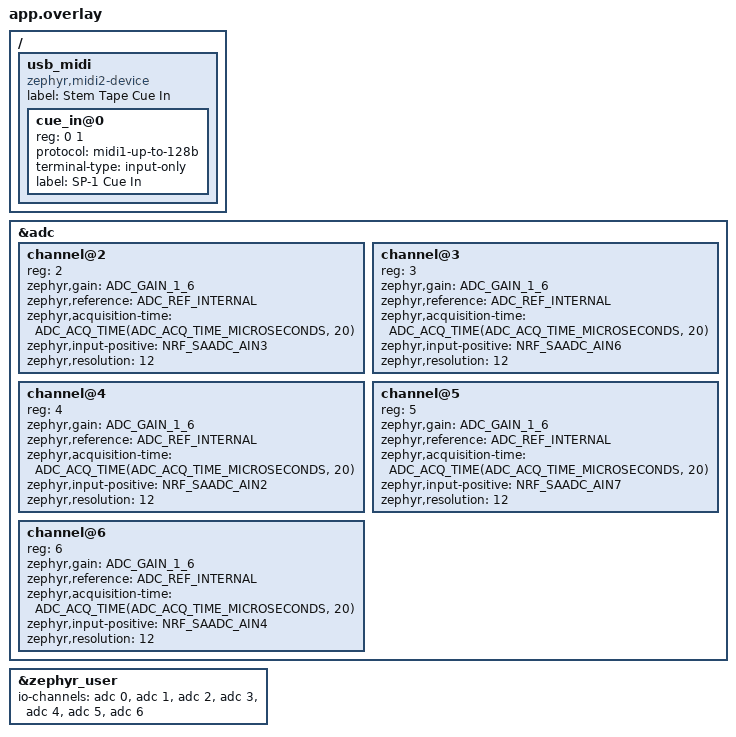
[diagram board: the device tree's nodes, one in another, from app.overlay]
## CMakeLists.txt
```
cmake_minimum_required(VERSION 3.20.0)
find_package(Zephyr REQUIRED HINTS $ENV{ZEPHYR_BASE})
project(stemtape-player)

include(${ZEPHYR_BASE}/samples/subsys/usb/common/common.cmake)

# src/main.c and src/sp1_emmc.c are real derivatives of the proven Tape
# Looper (firmware/src/main.c, firmware/src/sp1_emmc.c) -- see main.c's
# provenance banner.
#
# GATE 1: src/st_midi_queue.c is the pure, host-testable USB-MIDI receive
# decode + bounded event queue (see st_midi_queue.h). main.c's real
# rx_packet_cb is a thin adapter that calls st_midi_decode_ump32() on the
# incoming UMP word -- the SAME function tests/test_stemtape_player.c
# exercises on the host -- so this is genuinely linked, not a parallel
# unwired module.
#
# STEM TAPE v1.1 (docs/stem-tape-transfer-v1.1.md is the current,
# authoritative contract): src/st_crc32.c, src/st_checksum32.c,
# src/st_sector_v11.c, src/st_stix.c, src/st_stcp.c, src/st_ab_session.c --
# the real STIX v2 index parse/validate/select, STSC sector codec, A/B
# region layout + STCP capability reply, and the stateful write-safety
# session gate (see each header's own doc) -- are linked: main.c's real
# 'Q' handler and boot-time A/B selection call these SAME pure functions
# tests/test_stem_v11.c exercises against the frozen Lovable handoff
# fixtures. st_crc32.c is linked for st_stix.c's own record-integrity CRC
# (st_stix_block_crc()), not for any v1.0 purpose.
#
# Phase 2 slice 2: src/st_stem_mix.c -- the pure, real-time-safe 4-stem-
# to-stereo mixdown (see st_stem_mix.h's own doc) -- is now linked and
# genuinely called: main.c's looper_audio_block() (PASS C) calls
# st_stem_mix_frame() on frames st11_sector_decode_frame() decodes from a
# real stored song's own sector data, feeding the SP-1's existing physical
# I2S output. Was added unlinked, host-test-only, in an earlier commit
# (see git log); the slice-2 commit gave it its real caller, per this
# file's own established policy below.
#
# Phase 2 slice 3B: src/st_stem_stream.c -- the pure stored-song
# CONTINUOUS streaming state machine (see st_stem_stream.h's own doc) --
# is now linked and genuinely called: streamer_thread() seeds it from the
# selected song's own real STIX geometry and validates every sector (not
# just the first) through it; audio_thread (looper_audio_block()'s own
# PASS C) is its EXCLUSIVE owner as of slice 3B.1's concurrency
# correction, driving its per-frame song-position/sector-readiness/
# underrun bookkeeping. Was added unlinked, host-test-only, in slice 3A
# (see git log); slice 3B gave it its real caller, per this file's own
# established policy.
#
# Phase 2 slice 3B.1 (concurrency correction): src/st_stem_bufmbox.c --
# the formally specified, lock-free single-producer/single-consumer
# double-buffer publication mailbox (see st_stem_bufmbox.h's own full
# protocol spec) -- replaces slice 3B's `volatile`-fields-plus-
# documented-write-order cross-thread handoff between streamer_thread
# (producer) and audio_thread (consumer) with real atomics and acquire/
# release ordering. Compiled with -DST_STEM_BUFMBOX_ZEPHYR (below) so its
# atomic primitives resolve to Zephyr's own atomic_t, unconditionally
# sequentially consistent on every architecture Zephyr supports --
# strictly stronger than the acquire/release the protocol requires. The
# SAME source file, built instead against C11 <stdatomic.h> with the
# minimal acquire/release ordering the protocol actually needs, is what
# tests/test_stem_bufmbox.c's real concurrent-pthread host tests exercise
# (see that file's own doc comment for why that is a faithful stand-in,
# and where the faithfulness gap actually is).
#
# Phase 3 control-matrix (momentary hold-to-solo, corrected): src/
# st_track_hold.c -- the pure, host-tested momentary hold-timing state
# machine (see st_track_hold.h's own doc comment for the semantics, and
# why this replaced a first version that wrongly toggled solo once at
# release -- a latch, not the momentary behavior actually specified) --
# is linked and genuinely called: main.c's own track-button scan loop
# ticks one instance per track every scan pass, and looper_audio_block()/
# led_service() both read the resulting trk[].solo state it drives.
#
# Phase 3 control-matrix (beat-sync LED slice): src/st_beat_phase.c -- the
# pure, host-tested, RAM-only beat-phase computation (see that file's own
# doc comment: the selected STIX record's own bpm_q8/downbeat_frame are
# the sole authoritative tempo source, sector-header timing is cross-
# checked for consistency only, and phase is always re-derived from the
# master song_frame position's own atomic mirror -- never a second,
# independently-ticking clock) -- is linked and genuinely called: main.c's
# own streamer_thread() boot code publishes the timing snapshot once (from
# the SAME already-read STIX record slice 3B/3B.1 already consume for
# geometry), audio_block_epilogue() publishes the song-position mirror once
# per block, and led_service() calls st_beat_pulse() on both of those every
# control pass. EVERY function in this file has a real caller: the module
# once also exported st_beat_phase_on_beat()/st_beat_led_decide(), which
# lost their caller when the eight LEDs got a single semantic owner, and
# have since been DELETED rather than left compiled in and unreachable.
#
# The OLD, now-retired v1.0 Gate 2 contract's own engine -- src/
# st_storage_layout.c, src/st_sector_codec.c, src/st_transfer.c, src/
# st_library_io.c, src/st_xfer_wire.c, and src/st_stem_validate.c (an
# even earlier, already-superseded design within that same v1.0 line) --
# is DELIBERATELY NOT linked here: main.c no longer calls any command
# handler or adapter that reaches these files' functions at all (the
# v1.1 migration deleted that dispatch code, not merely disabled it), so
# there is no path from this target's command dispatch to their own
# emmc_write_blocks() call sites, and no v1.0 write path is ever present
# in this ELF -- v1.0 and v1.1 can never both hold a live write path in
# the same build, by construction. These files stay in the tree and keep
# their own host tests (tests/test_stemtape_player.c) for regression
# evidence only; a follow-up commit extends the strict persistence safety
# gate to check their symbols are absent from the built ELF directly, as
# positive proof rather than relying on this list alone.
#
# NOT included here (compiled only into tests/test_stemtape_player.c's host
# test binary, not into this firmware target): led_duty.c/led_render.c/
# led_render_policy.c, st_gesture.c, st_scrub.c, st_led_pattern.c --
# st_gesture.c/st_scrub.c/st_led_pattern.c implemented an earlier,
# superseded standalone protocol/runtime design (see git log); main.c
# still drives LEDs directly (its own GPIO+soft-PWM driver, inherited
# from the Tape Looper). Preserved and still host-tested for reference;
# deliberately NOT linked into this ELF so as not to present unwired
# modules as part of the real runtime.
#
# Upload-reliability phase, Slice C2: src/st_bulk_xfer.c -- the pure wire-
# contract parser/builder + per-session sequence state machine behind the
# new 'U' bulk verified-sector command (see st_bulk_xfer.h's own doc and
# docs/stem-tape-bulk-upload-v1.md) -- is now linked and genuinely called:
# main.c's real xfer_bulk_write_sector() (xfer_service()'s 'U' handler)
# calls st_bulk_parse_header()/st_bulk_build_response()/st_bulk_seq_check()/
# st_bulk_seq_advance() against the real CDC/eMMC environment. Was added
# unlinked, host-test-only, in Slice C1 (see git log); this slice gave it
# its real caller, per this file's own established policy (see
# st_stem_stream.c's own identical slice-3A/3B split above).
# Tape transport inertia: src/st_inertia.c -- the pure spin-up/spin-down
# envelope. It is a 0..1 multiplier on the transport rate and knows nothing
# about audio; main.c's stem run loop applies it to the shared playhead and
# src/st_resample.h (header-only, no translation unit) converts between the
# source-frame and output-frame domains that a rate other than 1x separates.
# Host-tested in tests/test_inertia.c.

# Rocker semitone control: src/st_pitch.c -- the song's pitch, on the same
# equal-tempered 2^(k/12) grid the inherited Tape Looper's own semitone
# double-click uses (firmware/src/main.c's k_semi_q16), subdivided to half
# steps. It is a tape varispeed: the value is a playback RATE, so pitch and
# time move together exactly as they do in the Looper, and no time-stretching
# was added. Host-tested in tests/test_pitch.c, which re-derives the Looper's
# whole-semitone table out of this one and compares it entry by entry.

# LED MVP (single semantic owner): src/st_led_mvp.c -- the pure,
# host-tested decision that turns real runtime state into one complete
# eight-LED frame, plus the local battery classifier (see st_led_mvp.h) --
# is linked and genuinely called: main.c's led_service() fills
# st_led_inputs_t from the live transport/mixer/charger state, calls
# st_led_mvp_decide(), and renders the result through the existing
# TIMER3/GPIO soft-PWM masks. It is the ONLY thing that writes those masks
# in normal running.
#
# RE-LINKED: src/st_stem_meter.c -- the per-stem envelope follower and
# brightness curve, one instance per stem.
#
# It was unlinked once, on the reasoning that "a level meter is not the
# stable readable indication the LED contract specifies -- a quiet passage
# dimmed a stem that was audible". That reasoning is reversed on the
# product's own terms: a quiet passage SHOULD dim its stem, because the Track
# row's job is to show what each part of the arrangement is doing, and a row
# that reads the same whether a stem is playing or resting shows nothing at
# all. The stable indication the contract wanted is the SIDE row, which still
# has it -- S4 carries the beat, unchanged.
#
# The module owns no clock and takes no tempo input; it converts a stream of
# per-stem peaks into a brightness. Host-tested in tests/test_stem_meter.c
# (the arithmetic) and tests/test_led_audio_reactive.c (the five acceptance
# behaviours, against synthesised drum/pad/vocal material).
target_sources(app PRIVATE
	src/main.c
	src/sp1_emmc.c
	src/st_midi_queue.c
	src/st_crc32.c
	src/st_checksum32.c
	src/st_sector_v11.c
	# v1.2 song-planar addressing. main.c's read path calls st_pl_group_block(),
	# st_pl_validate() and st_pl_decode_frame() on every fetch and every frame,
	# so this is not optional -- omitting it links to nothing and the build dies
	# at the first link pass with no zephyr.elf, which is exactly what happened.
	src/st_planar.c
	src/st_stix.c
	src/st_stcp.c
	src/st_ab_session.c
	src/st_bulk_xfer.c
	src/st_stem_mix.c
	src/st_stem_stream.c
	src/st_stem_bufmbox.c
	src/st_track_hold.c
	src/st_ladder.c
	src/st_ctl.c
	src/st_pwr_hold.c
	src/st_pwr_idle.c
	src/st_loop.c
	src/st_fx.c
	src/st_fx_ctl.c
	src/st_inertia.c
	src/st_pitch.c
	src/st_fnplay.c
	src/st_readcost.c
	src/st_beat_phase.c
	src/st_stem_meter.c
	src/st_led_mvp.c
)

# See firmware/CMakeLists.txt's identical note: the batchbuf/meta-block code
# (inherited unchanged in this derivative) type-puns static uint8_t[]
# storage through other lvalue types; -fno-strict-aliasing removes the TBAA
# assumption that would make that idiom undefined.
target_compile_options(app PRIVATE -fno-strict-aliasing)

# Selects st_stem_bufmbox.h's real-Zephyr-atomic_t backend for this
# firmware target only -- the host test build (plain `cc`, no Zephyr
# headers available) never defines this, so it takes the C11
# <stdatomic.h> backend instead. See st_stem_bufmbox.h's own doc comment.
target_compile_definitions(app PRIVATE ST_STEM_BUFMBOX_ZEPHYR)

target_link_libraries(app PRIVATE m)

# ---- AIN1 CALIBRATION CAPTURE ------------------------------------------
# OFF unless -DST_VOL_CAL=1 is passed on the west/cmake command line. An
# explicit hook rather than EXTRA_COMPILE_DEFINITIONS, which is not a
# dependable Zephyr variable across versions.
#
# The capture prints the raw AIN1 rail so the Volume-/Volume+ chord value can
# be measured; the FX overlay cannot decode that chord until it is. It must
# never reach a shipped image, which two independent checks enforce: the
# safety gate greps main.c's own #define, and the CI build compares `strings`
# on the two BINs.
if(ST_VOL_CAL)
  zephyr_compile_definitions(ST_VOL_CAL=1)
  message(STATUS "AIN1 CALIBRATION CAPTURE ENABLED -- not a shippable image")
endif()
```

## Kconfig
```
# Stem Tape Player application Kconfig.
#
# Pulls in the common USB sample options (CONFIG_SAMPLE_USBD_VID/PID/PRODUCT/...)
# consumed by the vendored sample_usbd_init.c device_next bring-up helper, then
# the standard Zephyr Kconfig tree. Mirrors firmware/Kconfig and
# firmware/stemtape/Kconfig exactly -- this file was simply never needed
# before src/main.c became a real derivative of the Tape Looper and started
# using CONFIG_SAMPLE_USBD_* (prj.conf) for its own USB device identity.

source "samples/subsys/usb/common/Kconfig.sample_usbd"

source "Kconfig.zephyr"
```

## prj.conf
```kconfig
# ---- Stem Tape Player: derived from the real Tape Looper's prj.conf ----
#
# src/main.c is now a real derivative of the proven firmware/src/main.c (see
# its provenance banner). USB device_next carries CDC console + class-
# compliant incoming USB-MIDI 2.0 (CONFIG_USBD_MIDI2_CLASS=y) only.
#
# STEM TAPE: UAC2 (USB audio class) playback -- CONFIG_USBD_AUDIO2_CLASS and
# its two feedback-workaround options below -- is REMOVED as of this change.
# Product decision: it was added earlier under the mistaken assumption that
# KO II cue control depended on it. Cue control actually uses incoming USB
# MIDI only, and song loading uses the companion's own transfer protocol
# over the CDC console (unaffected). Stored four-stem playback now
# exclusively owns the SP-1 audio output. See main.c's own top-of-file
# comment, and the CI "Effective configuration assertion" and "USB
# descriptor assertion" steps, which now prove CONFIG_USBD_AUDIO2_CLASS is
# unset and no UAC2 descriptor material is linked.
#
# Incoming MIDI drives KO II pad cue control via a standalone MIDI bridge;
# there is no outgoing MIDI and no MIDI clock in this slice. ADC (button
# ladders + faders), I2C (codec bring-up), I2S (audio out), watchdog, and
# the failsafes are all still needed, same as the classic looper. This file
# otherwise mirrors firmware/prj.conf (see that file for the per-option
# rationale comments); it does NOT invent any new Kconfig option beyond
# what firmware/prj.conf already proves builds and runs on this exact
# board, plus the MIDI2 option firmware/prj.conf itself documents.

CONFIG_PM=y
CONFIG_PM_DEVICE=n
CONFIG_LOG=n
CONFIG_ASSERT=n
CONFIG_USE_SEGGER_RTT=n
CONFIG_IDLE_STACK_SIZE=128
CONFIG_ISR_STACK_SIZE=512
CONFIG_WATCHDOG=y

# ---- FAILSAFES: catch stack overflow / bad memory access cleanly (MPU guard +
# stack canary). Any fatal fault is turned into a reboot by k_sys_fatal_error_handler
# in main.c, and the 4 s watchdog is the final backstop for a hang. ----
CONFIG_HW_STACK_PROTECTION=y
CONFIG_STACK_SENTINEL=y
CONFIG_REBOOT=y
CONFIG_CLOCK_CONTROL=y
CONFIG_CLOCK_CONTROL_NRF_K32SRC_SYNTH=y

# ---- USB-serial diagnostics console (CDC ACM) ----
CONFIG_PRINTK=y
CONFIG_SERIAL=y
CONFIG_CONSOLE=y
CONFIG_UART_CONSOLE=y
CONFIG_UART_LINE_CTRL=y
CONFIG_UART_INTERRUPT_DRIVEN=y

# ---- USB device_next: CDC console + incoming USB-MIDI only. ----
# SP1XFER!/xfer_service() still rides the CDC ACM console exactly as in
# the classic looper; every 'W'/'F'/'X' verb remains read-only-safe (see
# main.c). CONFIG_USBD_MIDI2_CLASS=y adds a class-compliant incoming-only
# USB-MIDI 2.0 endpoint (see app.overlay's usb_midi node and main.c's
# rx_packet_cb) -- no outgoing MIDI, no MIDI clock.
CONFIG_USB_DEVICE_STACK_NEXT=y
CONFIG_USBD_MIDI2_CLASS=y
CONFIG_USBD_CDC_ACM_CLASS=y
CONFIG_CDC_ACM_SERIAL_INITIALIZE_AT_BOOT=n
CONFIG_HWINFO=y
# Distinct PID from both the classic looper (0x5210) and stock SP-1 firmware,
# so a host never caches the wrong driver/identity across firmware swaps.
CONFIG_SAMPLE_USBD_VID=0x1915
CONFIG_SAMPLE_USBD_PID=0x5211
CONFIG_SAMPLE_USBD_MANUFACTURER="softmodded"
CONFIG_SAMPLE_USBD_PRODUCT="Stem Tape Audio"
CONFIG_THREAD_RUNTIME_STATS=y
CONFIG_SCHED_THREAD_USAGE=y
# STACK HIGH-WATER. Fills every thread stack with a known pattern at creation
# so k_thread_stack_space_get() can report how much has ever been touched.
# controls_diag() prints it on the STACK line. This exists because the RAM
# audit is not allowed to change a stack size from a guess: 12,672 bytes of
# stack are allocated across main/streamer/audio/midi/idle/ISR and none of
# those numbers has ever been measured against real use. Costs one memset per
# thread at boot and nothing at run time.
CONFIG_INIT_STACKS=y
CONFIG_SAMPLE_USBD_MAX_POWER=50

# ---- ADC for the button ladders / faders ----
CONFIG_ADC=y

# ---- I2C to the audio codecs (CS42L42 / TAS2505) ----
CONFIG_I2C=y

# ---- I2S audio out (nRF master) ----
CONFIG_I2S=y
CONFIG_I2S_NRFX=y
CONFIG_FPU=y
# See firmware/CMakeLists.txt's matching note: -O2 is unsafe for this
# codebase's mixer/eMMC timing (latent signed-overflow UB the classic looper
# already documents). Stay on the default -Os here too.

CONFIG_MAIN_STACK_SIZE=4096

# ---- Always-dim LEDs: the soft-PWM LED timer ISR (main.c's led_pwm_isr, on
# NRF_TIMER3) runs as a ZERO-LATENCY interrupt so kernel locks / other IRQs
# can't delay its on/off edges (edge jitter at low duty = visible flicker).
CONFIG_ZERO_LATENCY_IRQS=y
```

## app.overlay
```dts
#include <zephyr/dt-bindings/adc/adc.h>
#include <zephyr/dt-bindings/adc/nrf-saadc.h>
#include <zephyr/dt-bindings/pinctrl/nrf-pinctrl.h>

/* STEM TAPE: src/main.c is now a real derivative of the Tape Looper (see
 * its provenance banner) -- it drives the eight physical LEDs directly via
 * raw GPIO register access (leds[]/track_leds[] + the soft-PWM timer ISR,
 * NOT the Zephyr PWM peripheral), on exactly the same pins listed below.
 * This overlay previously (superseded design, see git history) claimed
 * those SAME pins for the hardware PWM2/PWM3 peripheral via pinctrl -- a
 * real pin-ownership conflict with main.c's raw-GPIO driver, for the exact
 * reason firmware/boards/teenageengineering/stem_player/stem_player.dts's
 * own comment already documents: "PWM owning those pins would fight" the
 * raw-GPIO row driver. That PWM2/PWM3 devicetree block (and the pwm-leds
 * container that exposed it to led_render.c, also no longer built into
 * this target -- see CMakeLists.txt) has been removed; this overlay now
 * only carries the ADC channel setup, identical to firmware/app.overlay,
 * which main.c's ladder_read()/adc_ladder[] actually depend on. */

&adc {
	channel@2 { reg = <2>; zephyr,gain = "ADC_GAIN_1_6"; zephyr,reference = "ADC_REF_INTERNAL";
		zephyr,acquisition-time = <ADC_ACQ_TIME(ADC_ACQ_TIME_MICROSECONDS, 20)>;
		zephyr,input-positive = <NRF_SAADC_AIN3>; zephyr,resolution = <12>; };   /* Fader 1 P0.05 */
	channel@3 { reg = <3>; zephyr,gain = "ADC_GAIN_1_6"; zephyr,reference = "ADC_REF_INTERNAL";
		zephyr,acquisition-time = <ADC_ACQ_TIME(ADC_ACQ_TIME_MICROSECONDS, 20)>;
		zephyr,input-positive = <NRF_SAADC_AIN6>; zephyr,resolution = <12>; };   /* Fader 2 P0.30 */
	channel@4 { reg = <4>; zephyr,gain = "ADC_GAIN_1_6"; zephyr,reference = "ADC_REF_INTERNAL";
		zephyr,acquisition-time = <ADC_ACQ_TIME(ADC_ACQ_TIME_MICROSECONDS, 20)>;
		zephyr,input-positive = <NRF_SAADC_AIN2>; zephyr,resolution = <12>; };   /* Fader 3 P0.04 */
	channel@5 { reg = <5>; zephyr,gain = "ADC_GAIN_1_6"; zephyr,reference = "ADC_REF_INTERNAL";
		zephyr,acquisition-time = <ADC_ACQ_TIME(ADC_ACQ_TIME_MICROSECONDS, 20)>;
		zephyr,input-positive = <NRF_SAADC_AIN7>; zephyr,resolution = <12>; };   /* Fader 4 P0.31 */
	channel@6 { reg = <6>; zephyr,gain = "ADC_GAIN_1_6"; zephyr,reference = "ADC_REF_INTERNAL";
		zephyr,acquisition-time = <ADC_ACQ_TIME(ADC_ACQ_TIME_MICROSECONDS, 20)>;
		zephyr,input-positive = <NRF_SAADC_AIN4>; zephyr,resolution = <12>; };   /* Battery level P0.28 (divider, per SP-1-dev wiki) */
};
&zephyr_user {
	io-channels = <&adc 0>, <&adc 1>, <&adc 2>, <&adc 3>, <&adc 4>, <&adc 5>, <&adc 6>;
};

/* GATE 1: class-compliant USB-MIDI 2.0 receive-only endpoint for KO II pad
 * cue control via a standalone MIDI bridge (the SP-1 stays a USB device; it
 * never becomes a USB host). This node is target-specific (main.c's real
 * DEVICE_DT_GET(DT_NODELABEL(usb_midi))) and stemtape_player-only -- the
 * shared board DTS (firmware/boards/teenageengineering/stem_player/
 * stem_player.dts, used by every target including the golden Tape Looper)
 * is untouched; this lives only in this target's own overlay. One
 * bidirectional Group Terminal Block, matching Zephyr's own usb/midi
 * sample's app.overlay exactly (compatible, #address-cells/#size-cells,
 * reg/protocol/terminal-type). "midi1-up-to-128b": KO II pad Note On/Off
 * are ordinary 3-byte MIDI 1.0 messages, well under 128 bits. */
/ {
	usb_midi: usb_midi {
		compatible = "zephyr,midi2-device";
		status = "okay";
		#address-cells = <1>;
		#size-cells = <1>;
		label = "Stem Tape Cue In";

		cue_in@0 {
			reg = <0 1>;
			protocol = "midi1-up-to-128b";
			terminal-type = "input-only";
			label = "SP-1 Cue In";
		};
	};
};
```

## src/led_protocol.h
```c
/*
 * led_protocol.h — Stem Tape standalone player: physical LED hardware
 * constants only.
 *
 * This is the PHYSICAL-LAYER SUBSET of firmware/stemtape/src/led_protocol.h
 * (the M0 diagnostic target's header), which also defines a MIDI
 * channel-16 wire protocol that does not apply here — the standalone
 * player drives its eight LEDs from LOCAL audio/gesture state
 * (st_led_pattern.h), never from a host MIDI connection. led_duty.h/.c and
 * led_render.h/.c are copied byte-for-byte from the M0 target (the same
 * physical PWM2/PWM3 hardware, unchanged) and need only the constants
 * below; keep this file's physical table in sync with the M0 target's if
 * either changes — see that header's "Evidence" section for the citation
 * trail this table is copied from.
 *
 *   idx | logical LED           | GPIO   | PWM instance | PWM channel
 *   ----+------------------------+--------+--------------+------------
 *    0  | Track 1                | P0.29  | PWM2         | 0
 *    1  | Track 2                | P0.26  | PWM2         | 1
 *    2  | Track 3                | P1.15  | PWM2         | 2
 *    3  | Track 4                | P1.14  | PWM2         | 3
 *    4  | Side, nearest PLAY     | P1.13  | PWM3         | 3
 *    5  | Side, PLAY-side middle | P0.00  | PWM3         | 2
 *    6  | Side, FUNCTION-side mid| P1.12  | PWM3         | 1
 *    7  | Side, nearest FUNCTION | P0.01  | PWM3         | 0
 *
 * Side-row PLAY-end/FUNCTION-end direction remains a best-effort
 * inference, not hardware-confirmed — see the M0 target's header.
 */

#ifndef STEMTAPE_PLAYER_LED_PROTOCOL_H_
#define STEMTAPE_PLAYER_LED_PROTOCOL_H_

#include <stdint.h>

#define LED_PHYSICAL_COUNT   8u

#define LED_IDX_TRACK1        0u
#define LED_IDX_TRACK2        1u
#define LED_IDX_TRACK3        2u
#define LED_IDX_TRACK4        3u
#define LED_IDX_SIDE_PLAY     4u
#define LED_IDX_SIDE_MID1     5u
#define LED_IDX_SIDE_MID2     6u
#define LED_IDX_SIDE_FUNCTION 7u

#define LED_TRACK_ROW_COUNT  4u
#define LED_SIDE_ROW_COUNT   4u

#define LED_PWM_PERIOD_US    1024u

#define LED_TRACK_MAX_PULSE_US  52u
#define LED_SIDE_MAX_PULSE_US   66u

#define LED_LEVEL_MAX        127u

#endif /* STEMTAPE_PLAYER_LED_PROTOCOL_H_ */
```

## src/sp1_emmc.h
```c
/*
 * SP-1 eMMC 1-bit bit-bang driver (Zephyr port of Tim Knapen's SP-1-dev emmc.c).
 * Toshiba THGBMNG5D1LBAIL, 4 GB, connected CLK/CMD/DAT0/RST_n + VCCQ only.
 * Ported to use the nrfx GPIO HAL + k_busy_wait so it builds in the Zephyr app.
 * The DATA-phase clock half-period is runtime-configurable (g_emmc_clk_half_us);
 * the firmware sets it to 0 (delay-free, fastest) after init. Commands/init
 * always use a fixed safe clock internally.
 */
#ifndef SP1_EMMC_H
#define SP1_EMMC_H

#include <stdint.h>
#include <stdbool.h>

/* Build selector (the only knob that differs between the two builds).
 *   0 = 48 kHz: flash bus at 32 MHz (M32), full rate.
 *   1 = 24 kHz: flash bus at the in-spec 16 MHz (M16). Half the data rate gives
 *       ~2x bandwidth headroom, so it stays rock-solid under a full 4-track load.
 *       The 32 MHz overclock (over the eMMC's 26 MHz spec) was what made an earlier
 *       24 kHz build glitch into white noise; M16 cures it. Both builds keep the
 *       eMMC write cache ON (it absorbs record bursts so writes don't stall the bus
 *       and crackle the playing tracks).
 * It drives DECIM (sample rate) and the SPIM flash clock. */
#ifndef SP1_BUILD_24K
#define SP1_BUILD_24K 0
#endif

#define EMMC_BLOCK_SIZE 512u

/* DATA-transfer clk half-period in microseconds. 0 = fastest (no busy-wait, just
 * GPIO register toggles); the streamer sets 0 after emmc_init(). Commands/init
 * always use a fixed safe clock internally. */
extern volatile uint32_t g_emmc_clk_half_us;
extern volatile uint32_t emmc_crc_rd_errs;   /* verified-read CRC catches  */
extern volatile uint32_t emmc_crc_wr_errs;   /* write status-token catches */

/* ---- diagnostics, filled by emmc_init() to pinpoint where bring-up fails ---- */
extern bool    emmc_dbg_cmd0_sent;
extern int     emmc_dbg_cmd1_retries;   /* retries until ready; -1 = never ready */
extern bool    emmc_dbg_cmd2_resp;
extern bool    emmc_dbg_cmd3_resp;
extern bool    emmc_dbg_cmd7_resp;
extern bool    emmc_dbg_cmd16_resp;
extern uint8_t emmc_dbg_ocr[6];          /* CMD1 R3 response bytes */
extern uint8_t emmc_dbg_r1[6];           /* CMD7 R1 response bytes */
/* Last single-block read/write command response flags (for read/write tests). */
extern bool    emmc_dbg_last_cmd_resp;
extern int     emmc_dbg_resp_clocks;   /* clocks until last response start bit (-1=none) */
extern int     emmc_dbg_cmd2_clocks;   /* clocks-to-response captured for CMD2 (-1=none) */
extern int     emmc_dbg_cmd2_tries;    /* CMD2 attempts before a response */
extern int     emmc_dbg_wr_status;     /* CRC status token from last block write:
					* 0b010=2 accepted, 0b101=5 CRC err, 0b110=6 write err, -1=none */
extern uint16_t emmc_dbg_rd_crc;
extern volatile uint32_t emmc_dbg_wr_busy_max;  /* diag: max post-write program busy-wait clk iterations */       /* CRC16 the card appended to the last read block */
/* Wall-clock stall diagnostics (us). THE numbers the crackle hunt needs: the
 * old iteration counters were uncalibrated and their silent expiry hid the
 * true stall length. window = reset by the diag printer; peak = session max. */
extern volatile uint32_t emmc_dbg_wr_busy_us_max;    /* worst write program-busy, us (window) */
extern volatile uint32_t emmc_dbg_wr_busy_us_peak;   /* worst write program-busy, us (session) */
extern volatile uint32_t emmc_dbg_rd_wait_us_max;    /* worst read start-bit access wait, us (window) */
extern volatile uint32_t emmc_dbg_switch_busy_us_max;/* worst R1b busy: CMD6 flush/BKOPS/TRIM, us */
extern volatile uint32_t emmc_dbg_busy_timeouts;     /* busy-poll expiries (SEPARATE from CRC errs) */
/* READ-PATH PHASE BREAKDOWN of the LATEST emmc_read_blocks() call (reset at
 * the top of each call, published on every exit path). Wall time, DWT-timed
 * at 64 MHz, so audio-thread preemption is attributed to whichever phase it
 * interrupted -- deliberate: the deficit these exist to explain IS a CPU
 * competition. hunt+dma+crc plus the CMD18/CMD12 handshake account for the
 * whole call, so comparing their sum against STEMIO's own rdus= says
 * directly where a sector read's time went. */
extern volatile uint32_t emmc_dbg_rd_hunt_us;        /* bit-banged start-bit hunt, all blocks */
extern volatile uint32_t emmc_dbg_rd_dma_us;         /* SPIM3 DMA of the payloads, all blocks */
extern volatile uint32_t emmc_dbg_rd_crc_us;         /* copy-out + CRC16 verify, all blocks */
extern volatile uint32_t emmc_dbg_rd_hunt_clks;      /* clock pulses the hunts cost, all blocks */
/* THE HUNT, SPLIT. hunt_us is wall time and therefore answers no question on
 * its own: a hunt of 3892 us that issued only 375 clock pulses is either a
 * loop costing 10 us per GPIO toggle (absurd) or a thread that was not
 * running for most of that window, and those two have opposite fixes. So the
 * window is measured twice:
 *
 *   spin_us  cycles actually spent inside the pulse burst, summed. Divided by
 *            hunt_clks this is the true cost of one clock pulse.
 *   gap_us   hunt_us - spin_us: the part of the hunt window in which no clock
 *            was being issued at all -- the k_usleep(50) long-stall yield,
 *            and any preemption landing between bursts.
 *
 * Preemption INSIDE a burst still lands in spin_us, which is why the ratio
 * spin_us/hunt_clks is the number to read: at 64 MHz a pulse is a GPIO write,
 * three nops and a GPIO read, so anything past ~0.5 us per pulse is not the
 * loop. */
extern volatile uint32_t emmc_dbg_rd_hunt_spin_us;   /* of hunt_us, spent issuing clock pulses */
extern volatile uint32_t emmc_dbg_rd_hunt_gap_us;    /* of hunt_us, spent not issuing any */
/* WORST SINGLE CLOCK PULSE of this read, in nanoseconds -- the number that
 * separates the last two candidates once spin_us is known. spin_us/hunt_clks is
 * an AVERAGE, and a burst preempted in its middle averages to the same figure
 * as a loop that is uniformly slow. This is per-burst cycles over that burst's
 * own pulse count, maximised, so: a uniformly slow loop gives max ~= average;
 * one descheduling gives exactly one enormous pulse and max >> average. */
extern volatile uint32_t emmc_dbg_rd_pulse_max_ns;
extern volatile uint32_t emmc_dbg_hpi_fires;         /* HPI aborts issued (maintenance ops cut short) */


bool emmc_init(void);
bool emmc_is_ready(void);
bool emmc_cmd13(uint8_t *r1_out);      /* SEND_STATUS — card status register R1 */
bool emmc_read_ext_csd(uint8_t *buf);  /* CMD8 SEND_EXT_CSD -> 512-byte EXT_CSD (read-only) */
bool emmc_cache_enable(void);          /* EXT_CSD CACHE_CTRL=1 (volatile write cache on) */
bool emmc_cache_flush(void);           /* EXT_CSD FLUSH_CACHE=1 (program cache to NAND) */
/* FTL-maintenance ops (eMMC 4.5+/5.0). ALL fail-safe: gate on the EXT_CSD
 * support bytes and treat any false return as "carry on without". */
bool emmc_trim(uint32_t start_blk, uint32_t end_blk, uint32_t busy_us);
bool emmc_cache_flush_try(void);       /* ABORTABLE flush for mid-session idle windows (needs HPI) */
bool emmc_hpi_enable(void);            /* EXT_CSD HPI_MGMT[161]=1; gate on HPI_FEATURES[503] bit0 */
void emmc_set_abort_cb(bool (*cb)(void)); /* busy-abort hook polled by abortable R1b waits */
bool emmc_bkops_auto_enable(void);     /* EXT_CSD[163] |= AUTO_EN (SET-BITS; reversible, never touches OTP MANUAL_EN) */
bool emmc_pon_powered_on(void);        /* EXT_CSD[34]=1 POWERED_ON (boot) */
bool emmc_pon_power_off_short(void);   /* EXT_CSD[34]=2 POWER_OFF_SHORT (shutdown, after the cache flush) */
bool emmc_read_blocks(uint32_t block_addr, uint8_t *buf, uint32_t count);
void emmc_power_down(void);            /* power-off: release bus pins + cut the VCCQ rail */
bool emmc_spim_active(void);           /* diag: true = 32MHz SPIM3 DMA path live, false = bit-bang */
bool emmc_write_blocks(uint32_t block_addr, const uint8_t *buf, uint32_t count);

#endif /* SP1_EMMC_H */
```

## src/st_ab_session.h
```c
/*
 * st_ab_session.h — the v1.1 write-safety SESSION gate.
 *
 * st11_region_of_block() (st_stcp.h) only proves an address falls inside
 * ONE OF THE FOUR permitted v1.1 regions -- it says nothing about which
 * pair is the CURRENT active (protected) one and which is the frozen
 * inactive (writable) destination for a specific in-flight replacement.
 * That is not a stateless, per-call fact: it depends on a snapshot of the
 * library taken once at the start of a replacement (or explicit-init)
 * attempt and held fixed for its whole duration, exactly as docs section 5
 * step 1 requires ("Re-query Q immediately before writing... or nothing is
 * written") and step 7 requires ("The active song and index are never
 * touched from here on").
 *
 * This module owns that snapshot. A caller (main.c's real 'W' handler,
 * once wired) must:
 *   1. Open exactly one session (st_ab_session_open_replace() for a normal
 *      upload, st_ab_session_open_init() ONLY for an explicit,
 *      already-token-confirmed initialization) before any write.
 *   2. Call st_ab_session_check_write() for EVERY block before writing it
 *      -- never write first and check after.
 *   3. For a REPLACE session, actually perform
 *      st_ab_session_verify_song_before_commit() (real I/O: reads the
 *      frozen song region back and recomputes its checksums) and call
 *      st_ab_session_mark_song_verified() BEFORE attempting the magic-
 *      committing write -- the gate itself refuses that write otherwise;
 *      this firmware never takes the companion's read-back claims on
 *      faith.
 *   4. Once st_ab_session_check_write() accepts a magic-committing write,
 *      the session becomes single-use (st_ab_session_close() or the gate's
 *      own internal latch) -- every FURTHER write, including to the just-
 *      superseded former-active pair (now the rollback copy), is refused
 *      until a NEW session is opened, which re-reads the (now-updated)
 *      library fresh rather than reusing any stale state.
 *
 * PURE except st_ab_session_verify_song_before_commit(), which needs
 * caller-injected block-read I/O (matching st_transfer.h's convention) to
 * do its job; every other function here is pure computation over
 * caller-supplied bytes.
 */

#ifndef STEMTAPE_PLAYER_AB_SESSION_H_
#define STEMTAPE_PLAYER_AB_SESSION_H_

#include <stdbool.h>
#include <stdint.h>

#include "st_stcp.h"
#include "st_stix.h"
#include "st_v11_format.h"

typedef enum {
	ST_AB_SESSION_NONE = 0,
	ST_AB_SESSION_REPLACE, /* normal upload: replaces the currently active song+index */
	ST_AB_SESSION_INIT,    /* explicit initialization: only legal when both indexes are invalid/blank */
} st_ab_session_kind_t;

typedef struct {
	bool open;
	bool closed;         /* single-use latch: set once a magic-committing write is accepted */
	bool song_verified;  /* REPLACE only: set only via st_ab_session_mark_song_verified() */
	st_ab_session_kind_t kind;
	st11_region_layout_t layout; /* frozen at open time */
	uint32_t active_song_slot;   /* ST11_NO_SLOT if none */
	uint32_t active_index_slot;  /* ST11_NO_SLOT if none */
	uint32_t inactive_song_slot; /* the ONLY song slot this session may ever write */
	uint32_t inactive_index_slot; /* the ONLY index slot this session may ever write */
	uint64_t active_generation;   /* generation at open time; a commit record must declare
					* exactly active_generation+1 (or exactly 1 for INIT) */
	uint32_t needed_song_blocks;  /* REPLACE only: the CEILING this session may write/commit
					* up to (the frozen region's own capacity, or a tighter
					* bound a caller who somehow knows the exact song size
					* may choose to pass) -- NOT necessarily the exact size
					* of the song actually being uploaded; the real wire
					* protocol has no verb to declare that before writes
					* begin (docs section 1), so a real caller can only
					* ever know the region's own capacity in advance */
	/* Incremental commit-verification state (REPLACE only). See
	 * st_ab_session_accumulate_sector() for what these mean and why they
	 * exist; all three are reset by both open_*() entry points. */
	bool acc_valid;       /* false once anything broke the strict, gapless order */
	uint32_t acc_sectors; /* how many sectors have been accumulated, from 0 upward */
	uint32_t acc_stem_hash[ST11_STEM_COUNT];
	/* The v1.2 song-planar group scan's position: which (stem, group) the
	 * next group read must be, in the stem-major order the layout defines.
	 * acc_groups_per_stem is 0 until the first stem transition TEACHES it
	 * the song's group count -- nothing declares that before the upload
	 * finishes -- after which every later transition must match it, and
	 * st_ab_session_verify_accumulated() checks the learned number against
	 * the record that finally arrives. */
	uint32_t acc_next_stem;
	uint32_t acc_next_group;
	uint32_t acc_groups_per_stem;
} st_ab_session_t;

typedef enum {
	ST_AB_OPEN_OK = 0,
	ST_AB_OPEN_ERR_NOT_INITIALIZED,     /* REPLACE: the library requires initialization --
					      * there is no valid active record to replace */
	ST_AB_OPEN_ERR_ALREADY_INITIALIZED, /* INIT: the library does NOT require initialization --
					      * refuses to clobber a valid library; docs section 7:
					      * "legal only when both index records are invalid
					      * or blank" */
	ST_AB_OPEN_ERR_NOT_CONFIRMED,       /* INIT: caller did not pass an explicit confirmation --
					      * this function never infers consent */
	ST_AB_OPEN_ERR_CAPACITY,            /* REPLACE: the song does not fit the frozen inactive
					      * song region (docs section 5 step 6,
					      * InsufficientStagingCapacityError) */
} st_ab_open_result_t;

/*
 * Opens a REPLACE session: reads both index blocks fresh (st_stix_read_library()),
 * freezes the resulting inactive_song_slot, inactive_index_slot, active
 * slots, and generation,
 * and checks `needed_song_blocks` fits the frozen song region's real capacity
 * -- `needed_song_blocks` is a CEILING a commit record's own song_block_count
 * must not exceed (typically the region's own full capacity, since the real
 * wire protocol gives no way to know the exact song size in advance; see
 * st_ab_session_t's own field comment). Refuses (session left closed/
 * unusable) if the library requires initialization or `needed_song_blocks`
 * itself does not fit the region.
 */
st_ab_open_result_t st_ab_session_open_replace(st_ab_session_t *s,
						const uint8_t block_a[ST11_PHYSICAL_BLOCK_BYTES],
						const uint8_t block_b[ST11_PHYSICAL_BLOCK_BYTES],
						const st11_region_layout_t *layout,
						uint32_t needed_song_blocks);

/*
 * Opens an INIT session: legal ONLY when st_stix_read_library() reports
 * requires_initialization (both index blocks invalid or blank) AND
 * `confirmed` is true -- `confirmed` must come from the caller's own
 * verification of an explicit destructive-confirmation token (mirroring
 * st_transfer.h's st_xfer_check_token()), never inferred here. An INIT
 * session's only two writable blocks are index B (docs section 7: written
 * as explicit zeros) and index A (the new generation-1, song-free
 * record); no song region is ever writable in an INIT session.
 */
st_ab_open_result_t st_ab_session_open_init(st_ab_session_t *s,
					     const uint8_t block_a[ST11_PHYSICAL_BLOCK_BYTES],
					     const uint8_t block_b[ST11_PHYSICAL_BLOCK_BYTES],
					     const st11_region_layout_t *layout, bool confirmed);

typedef enum {
	ST_AB_WRITE_OK = 0,
	ST_AB_WRITE_ERR_NO_SESSION,          /* no session open (or it was never opened successfully) */
	ST_AB_WRITE_ERR_SESSION_CLOSED,      /* this session already committed -- single-use */
	ST_AB_WRITE_ERR_ACTIVE_REGION,       /* block is inside the CURRENT active song or index region */
	ST_AB_WRITE_ERR_OUTSIDE_FROZEN_PAIR, /* block is a v1.1 region address, or unrelated storage,
					       * but not this session's frozen destination */
	ST_AB_WRITE_ERR_BAD_COMMIT_RECORD,   /* the block IS the frozen index destination, `data`
					       * carries the validity magic, but the record fails
					       * CRC/version/slot-identity/geometry/bounds, or its
					       * song reference does not name THIS session's own
					       * frozen song slot/start/size */
	ST_AB_WRITE_ERR_WRONG_GENERATION,    /* the commit record's generation != active_generation+1
					       * (INIT: != 1) */
	ST_AB_WRITE_ERR_SONG_NOT_VERIFIED,   /* REPLACE: a magic-committing write was attempted before
					       * st_ab_session_mark_song_verified() was ever called --
					       * this firmware never activates a record on the
					       * companion's word alone */
} st_ab_write_check_t;

/*
 * THE per-block gate. Must be called, and must return ST_AB_WRITE_OK,
 * before `data` is ever actually written to `block`. `data` is examined
 * only when `block` is this session's frozen index destination -- for any
 * other accepted block (a song-region write) the bytes are opaque audio
 * payload and are not interpreted here at all.
 */
st_ab_write_check_t st_ab_session_check_write(st_ab_session_t *s, uint32_t block,
					       const uint8_t data[ST11_PHYSICAL_BLOCK_BYTES]);

typedef int (*st11_block_read_fn)(uint32_t block, uint8_t out[ST11_PHYSICAL_BLOCK_BYTES], void *ctx);

/*
 * REPLACE only. Reads back every block of the session's frozen song
 * region via `read_fn` (real I/O, injected -- matches st_transfer.h's
 * convention so this is host-testable against an in-memory mock),
 * decodes it with the real STSC codec (st_sector_v11.h), and recomputes
 * every stem's FNV-1a checksum plus the song checksum EXACTLY as
 * test_stem_v11.c's own proven song-fixture logic does. Returns true
 * only if all five recomputed checksums (4 stems + song) match
 * `candidate`'s declared values -- this firmware verifies the bytes
 * actually on the media, never trusting the companion's own claim that
 * its upload succeeded. `scratch_sector` is a caller-owned
 * ST11_SECTOR_BYTES buffer (the one physical sector-sized buffer a
 * commit session needs, not allocated here). Does not open, close, or
 * otherwise mutate `s`; call st_ab_session_mark_song_verified() yourself
 * once this returns true.
 */
bool st_ab_session_verify_song_before_commit(const st_ab_session_t *s, const st_stix_record_t *candidate,
					      st11_block_read_fn read_fn, void *ctx,
					      uint8_t scratch_sector[ST11_SECTOR_BYTES]);

/*
 * Records that st_ab_session_verify_song_before_commit() was actually run
 * and returned true. This function does not itself re-verify anything --
 * it is the caller's explicit attestation, exactly like
 * st_xfer_commit_precheck()'s existing `verified` flag in st_transfer.h.
 * Calling it without having genuinely verified first defeats the
 * guarantee this module exists to provide; nothing else in this API
 * calls it for you.
 */
void st_ab_session_mark_song_verified(st_ab_session_t *s);

/*
 * INCREMENTAL alternative to st_ab_session_verify_song_before_commit(),
 * for callers that already read every sector back off the media as they
 * wrote it (the bulk verified-sector upload path does exactly that: it
 * writes a sector, reads the SAME blocks back, and CRCs the read-back
 * bytes before acknowledging).
 *
 * Why this exists: the full verify above re-reads the ENTIRE song region
 * a second time, inside the single wire command that carries the commit
 * record. For a real 248.5 MiB song that is over half a million block
 * reads plus a full decode of every audio frame -- minutes of work, with
 * the host waiting on one acknowledgement, and (before this was fixed)
 * with nothing feeding the hardware watchdog. It is also entirely
 * redundant work: the bytes it re-reads are the same bytes the bulk path
 * already read back off the media moments earlier.
 *
 * This accumulates the identical per-stem checksums from the read-back
 * bytes the caller ALREADY has in hand, one sector at a time, so the
 * commit itself costs nothing. The safety claim is unchanged and is NOT
 * weakened: the checksums are still computed from bytes genuinely read
 * back off the media, never from anything the companion merely claimed.
 * The only difference is when the reading happened.
 *
 * `sector` must be the READ-BACK bytes for `sector_index` (what storage
 * returned), never the bytes as received from the host. Sectors must
 * arrive strictly in order with no gaps, starting at 0: a sector_index
 * that skips ahead, or a sector whose four v1.2 GROUP HEADERS do not
 * continue the stem-major scan (stem 0 counting up from group 0, then one
 * step to stem 1 group 0, and so on, every stem the same length),
 * permanently invalidates the accumulation (acc_valid false) so
 * st_ab_session_verify_accumulated() then refuses and the caller must fall
 * back to the full re-read. A sector_index BELOW the running count is
 * treated as a harmless duplicate (an idempotent retry of an
 * already-accumulated sector) and is ignored rather than invalidating.
 * No-op unless this is an open, unclosed REPLACE session.
 *
 * v1.2 ONLY, deliberately. This is the fast path for the layout the
 * firmware actually stores. v1.1 INTERLEAVED read-back bytes are not
 * accumulable here -- they invalidate, and the fallback above carries the
 * commit, because st_ab_session_verify_song_before_commit() dispatches on
 * the version the RECORD declares and can still verify them. Guessing at a
 * layout would be the one thing this module must never do.
 */
void st_ab_session_accumulate_sector(st_ab_session_t *s, uint32_t sector_index,
				      const uint8_t sector[ST11_SECTOR_BYTES]);

/*
 * REPLACE only. Returns true only if st_ab_session_accumulate_sector()
 * covered EXACTLY `candidate`'s whole declared song -- gaplessly, in
 * order, from sector 0 through sector_count-1 -- and every resulting
 * checksum (4 stems + the song checksum derived from them) matches what
 * `candidate` declares, using byte-for-byte the same derivation as
 * st_ab_session_verify_song_before_commit(). Any shortfall, overshoot or
 * invalidation returns false, in which case the caller must fall back to
 * the full re-read rather than treating this as a verification failure.
 * Like the full verify, it does not mutate `s`; call
 * st_ab_session_mark_song_verified() yourself once this returns true.
 */
bool st_ab_session_verify_accumulated(const st_ab_session_t *s, const st_stix_record_t *candidate);

/* Explicitly ends a session (idempotent). Every subsequent
 * st_ab_session_check_write() call on it returns ST_AB_WRITE_ERR_SESSION_CLOSED.
 * st_ab_session_check_write() also calls this internally the moment it
 * accepts a magic-committing write, so an explicit call here is only
 * needed to abandon a session early (e.g. on error/abort). */
void st_ab_session_close(st_ab_session_t *s);

#endif /* STEMTAPE_PLAYER_AB_SESSION_H_ */
```

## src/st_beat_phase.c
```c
/*
 * st_beat_phase.c — see st_beat_phase.h.
 */

#include "st_beat_phase.h"

#include <limits.h>

bool st_beat_timing_init(st_beat_timing_t *out, uint32_t bpm_q8, uint32_t downbeat_frame, uint32_t sample_rate)
{
	out->downbeat_frame = downbeat_frame;
	out->frames_per_beat = 0u;

	if (bpm_q8 == 0u || sample_rate == 0u) {
		return false;
	}

	/* frames_per_beat = sample_rate * 60 / real_bpm, real_bpm = bpm_q8 / 256
	 *                 = sample_rate * 60 * 256 / bpm_q8
	 * rounded to the nearest whole frame (add half the divisor before the
	 * integer divide) -- 64-bit intermediate, no floating point. */
	uint64_t numerator = (uint64_t)sample_rate * 60ull * 256ull;
	uint64_t rounded = (numerator + (uint64_t)(bpm_q8 / 2u)) / (uint64_t)bpm_q8;

	if (rounded == 0u || rounded > (uint64_t)UINT32_MAX) {
		return false; /* absurd bpm/sample_rate combination -- fail closed, never wrap */
	}
	out->frames_per_beat = (uint32_t)rounded;
	return true;
}

void st_beat_pulse(const st_beat_timing_t *timing, uint32_t song_frame,
		    st_beat_pulse_t *out)
{
	uint32_t since, into_beat, window, last, half, rise;

	out->valid = false;
	out->in_pulse = false;
	out->envelope = 0u;
	out->beat_index = 0u;

	/* Fail closed: no tempo, or not yet at the first downbeat, means no
	 * pulse and no bar position -- not an invented one. */
	if (timing->frames_per_beat == 0u) {
		return;
	}
	if (song_frame < timing->downbeat_frame) {
		return;
	}

	since = song_frame - timing->downbeat_frame;
	out->beat_index = (uint8_t)((since / timing->frames_per_beat) & 3u);
	out->valid = true;

	into_beat = since % timing->frames_per_beat;
	window = (timing->frames_per_beat * ST_BEAT_PULSE_NUM) / ST_BEAT_PULSE_DEN;
	if (window == 0u) {
		return;   /* absurdly fast tempo: no window to light */
	}
	if (into_beat >= window) {
		return;   /* between pulses: dark, which is the point */
	}

	out->in_pulse = true;

	/* Symmetric triangle: 0 at both edges of the window, exactly 255 at its
	 * centre. Measured as the distance to the NEARER edge, which is
	 * symmetric by construction -- an earlier version scaled a rising/
	 * falling branch by window/2 and so peaked at 254, never at the 255 this
	 * module documents, and left a flat plateau on odd-length windows. */
	last = window - 1u;
	rise = (into_beat <= (last - into_beat)) ? into_beat : (last - into_beat);
	half = last / 2u;    /* the centre's own distance to the nearer edge */
	if (half == 0u) {
		out->envelope = 255u;   /* window of 1-2 frames: no room for a ramp */
		return;
	}
	out->envelope = (uint8_t)((rise * 255u) / half);
}
```

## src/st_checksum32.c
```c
/*
 * st_checksum32.c — see st_checksum32.h. PURE.
 */

#include "st_checksum32.h"

uint32_t st_checksum32_update(uint32_t h, const uint8_t *data, size_t len)
{
	size_t i;

	for (i = 0; i < len; i++) {
		h ^= data[i];
		h = h * 0x01000193u; /* FNV prime, mod 2^32 via natural uint32_t wrap */
	}
	return h;
}

uint32_t st_checksum32_compute(const uint8_t *data, size_t len)
{
	return st_checksum32_update(ST_CHECKSUM32_INIT, data, len);
}

uint32_t st_checksum32_unfold_zeros(uint32_t h, size_t count)
{
	size_t i;

	/* h' = (h ^ 0) * PRIME  ==  h * PRIME, so the step inverts to a
	 * single multiply by PRIME's modular inverse. The multiplicative
	 * group mod 2^32 contains every odd number, and 0x01000193 is odd,
	 * so the inverse exists and is exact -- this is not an
	 * approximation of the un-fold, it IS the un-fold. */
	for (i = 0; i < count; i++) {
		h = h * ST_CHECKSUM32_PRIME_INV;
	}
	return h;
}
```
